# CH32V20xxx register map
Vendor: WCH Ltd.; File version: 1.0
Registers are 32-bit, read-write, reset 0x0 unless marked. A register's access mark holds for its fields unless they carry their own. Offsets are from the block's base; [hi:lo] are bit positions.

## ETHERNET_PTP — Ethernet: Precision time protocol
Base 0x40028700
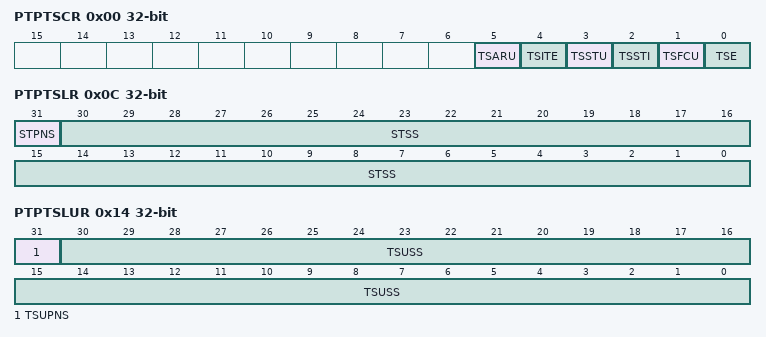
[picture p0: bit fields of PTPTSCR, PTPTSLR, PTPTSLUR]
0x00 PTPTSCR — Ethernet PTP time stamp control register (ETH_PTPTSCR)
  [5] TSARU — Time stamp addend register update
  [4] TSITE — Time stamp interrupt trigger enable
  [3] TSSTU — Time stamp system time update
  [2] TSSTI — Time stamp system time initialize
  [1] TSFCU — Time stamp fine or coarse update
  [0] TSE — Time stamp enable
0x04 PTPSSIR — Ethernet PTP subsecond increment register
  [7:0] STSSI — System time subsecond increment
0x08 PTPTSHR ro — Ethernet PTP time stamp high register
  [31:0] STS — System time second
0x0C PTPTSLR ro — Ethernet PTP time stamp low register (ETH_PTPTSLR)
  [31] STPNS — System time positive or negative sign
  [30:0] STSS — System time subseconds
0x10 PTPTSHUR — Ethernet PTP time stamp high update register
  [31:0] TSUS — Time stamp update second
0x14 PTPTSLUR — Ethernet PTP time stamp low update register (ETH_PTPTSLUR)
  [31] TSUPNS — Time stamp update positive or negative sign
  [30:0] TSUSS — Time stamp update subseconds
0x18 PTPTSAR — Ethernet PTP time stamp addend register
  [31:0] TSA — Time stamp addend
0x1C PTPTTHR — Ethernet PTP target time high register
  [31:0] TTSH — Target time stamp high
0x20 PTPTTLR — Ethernet PTP target time low register
  [31:0] TTSL — Target time stamp low

## DAC — Digital to analog converter
Base 0x40007400
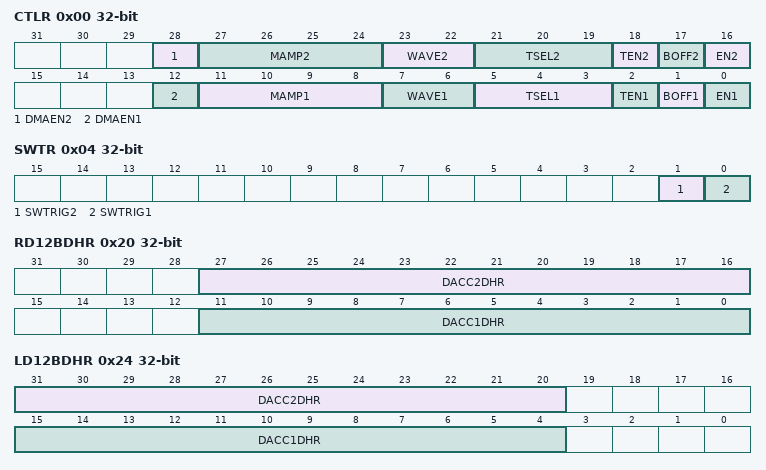
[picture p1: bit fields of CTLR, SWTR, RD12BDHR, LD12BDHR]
0x00 CTLR — Control register (DAC_CR)
  [28] DMAEN2 — DAC channel2 DMA enable
  [27:24] MAMP2 — DAC channel2 mask/amplitude selector
  [23:22] WAVE2 — DAC channel2 noise/triangle wave generation enable
  [21:19] TSEL2 — DAC channel2 trigger selection
  [18] TEN2 — DAC channel2 trigger enable
  [17] BOFF2 — DAC channel2 output buffer disable
  [16] EN2 — DAC channel2 enable
  [12] DMAEN1 — DAC channel1 DMA enable
  [11:8] MAMP1 — DAC channel1 mask/amplitude selector
  [7:6] WAVE1 — DAC channel1 noise/triangle wave generation enable
  [5:3] TSEL1 — DAC channel1 trigger selection
  [2] TEN1 — DAC channel1 trigger enable
  [1] BOFF1 — DAC channel1 output buffer disable
  [0] EN1 — DAC channel1 enable
0x04 SWTR wo — DAC software trigger register (DAC_SWTRIGR)
  [1] SWTRIG2 — DAC channel2 software trigger
  [0] SWTRIG1 — DAC channel1 software trigger
0x08 R12BDHR1 — DAC channel1 12-bit right-aligned data holding register(DAC_DHR12R1)
  [11:0] DACC1DHR — DAC channel1 12-bit right-aligned data
0x0C L12BDHR1 — DAC channel1 12-bit left aligned data holding register (DAC_DHR12L1)
  [15:4] DACC1DHR — DAC channel1 12-bit left-aligned data
0x10 R8BDHR1 — DAC channel1 8-bit right aligned data holding register (DAC_DHR8R1)
  [7:0] DACC1DHR — DAC channel1 8-bit right-aligned data
0x14 R12BDHR2 — DAC channel2 12-bit right aligned data holding register (DAC_DHR12R2)
  [11:0] DACC2DHR — DAC channel2 12-bit right-aligned data
0x18 L12BDHR2 — DAC channel2 12-bit left aligned data holding register (DAC_DHR12L2)
  [15:4] DACC2DHR — DAC channel2 12-bit left-aligned data
0x1C R8BDHR2 — DAC channel2 8-bit right-aligned data holding register (DAC_DHR8R2)
  [7:0] DACC2DHR — DAC channel2 8-bit right-aligned data
0x20 RD12BDHR — Dual DAC 12-bit right-aligned data holding register (DAC_DHR12RD), Bits 31:28 Reserved, Bits 15:12 Reserved
  [27:16] DACC2DHR — DAC channel2 12-bit right-aligned data
  [11:0] DACC1DHR — DAC channel1 12-bit right-aligned data
0x24 LD12BDHR — DUAL DAC 12-bit left aligned data holding register (DAC_DHR12LD), Bits 19:16 Reserved, Bits 3:0 Reserved
  [31:20] DACC2DHR — DAC channel2 12-bit right-aligned data
  [15:4] DACC1DHR — DAC channel1 12-bit left-aligned data
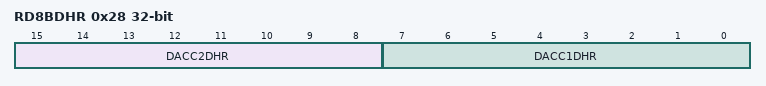
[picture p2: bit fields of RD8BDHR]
0x28 RD8BDHR — DUAL DAC 8-bit right aligned data holding register (DAC_DHR8RD), Bits 31:16 Reserved
  [15:8] DACC2DHR — DAC channel2 8-bit right-aligned data
  [7:0] DACC1DHR — DAC channel1 8-bit right-aligned data
0x2C DOR1 ro — DAC channel1 data output register (DAC_DOR1)
  [11:0] DACC1DOR — DAC channel1 data output
0x30 DOR2 ro — DAC channel2 data output register (DAC_DOR2)
  [11:0] DACC2DOR — DAC channel2 data output
